# YTM32B1LE0 register map
Vendor: YTMicro; File version: 1.9
CPU: CM0PLUS r0p1, little endian, MPU, FPU, 2 interrupt priority bits
Registers are 32-bit, read-write, reset 0x0 unless marked. A register's access mark holds for its fields unless they carry their own. Offsets are from the block's base; [hi:lo] are bit positions; 'fields as' and 'values as' point back to an identical list.

## PCU — Power control unit
Base 0x4007D000; register names take the prefix PCU_
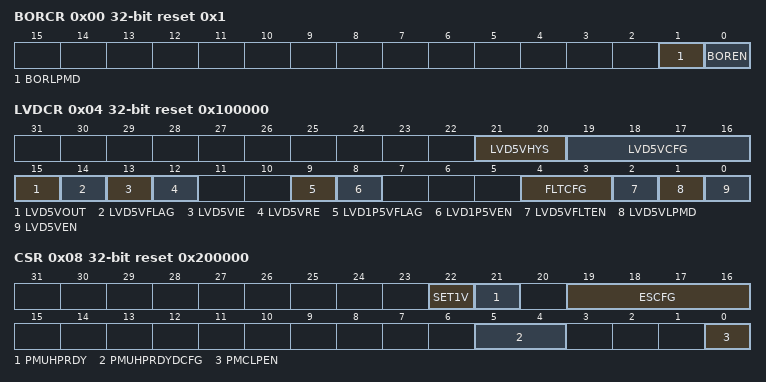
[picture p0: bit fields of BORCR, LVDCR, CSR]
0x00 BORCR reset 0x1
  [1] BORLPMD — BORLPMD Enable BOR Low Power Mode. That means BOR is enabled intermittently to saving power. The Power Saving efficiency is defined by ESCFG. BOREN must be set when BOR enters low power mode.
    0=BOR is not in Low Power Mode; 1=BOR is in Low Power Mode(Energy Saving Mode)
  [0] BOREN — BOREN Enable the BOR module. When BOR is enabled, a bor reset occurs when the chip power supply voltage falls below BOR threshold voltage(about 2.2V).
    0=BOR is disabled; 1=BOR is enabled
0x04 LVDCR reset 0x100000
  [21:20] LVD5VHYS — This field configure the LVD Hysteresis.
    0=0mV; 1=+­ 2.0%; 2=+­ 4.2%; 3=+­ 8.4%
  [19:16] LVD5VCFG — This field configures the LVD5V Threshold Voltage.
    0=1.860V; 1=2.120V; 2=2.370V; 3=2.630V; 4=2.870V; 5=3.120V; 6=3.390V; 7=3.650V; 8=3.910V; 9=4.160V; 10=4.360V; 11=4.530V; 12=4.720V; 13=4.910V
  [15] LVD5VOUT ro — This read only bit reflects the LVD5V detection result. If LVD5V glitch filter is enabled, this bit shows the filtered result.
    0=The supply voltage 5v is above LVD threshold; 1=The supply voltage 5v is below LVD threshold
  [14] LVD5VFLAG — Write 1 to clear this flag.
    values as LVD5VOUT
  [13] LVD5VIE — Enable/Disable LVD5V interrupt.
    0=Don't assert interrupt when LVD5VFLAG is set; 1=Assert a PCU interrupt when LVD5VFLAG is set
  [12] LVD5VRE — Enable/Disable LVD5V reset.
    0=Don't generate reset when the supply voltage 5v is below LVD threshold; 1=Generate reset when the supply voltage 5v is below LVD threshold
  [9] LVD1P5VFLAG — Write 1 to clear this flag.
    0=The supply voltage 1.5v is above LVD threshold; 1=The supply voltage 1.5v is below LVD threshold
  [8] LVD1P5VEN — LVD1P5VEN enable the low-voltage detect of VDD1p5v.
    0=LVD is disabled; 1=LVD is enabled
  [4:3] FLTCFG — There’s an optional digital glitch filter for LVD5VOUT. The Filter Clock is SIRC divided by 64 (31.25KHz) and the glitch filter width can be configured by FLTCFG. The glitches that width is shorter than (FLTCFG+1)*(the period of SIRC multiplied by 64) can be filtered.
  [2] LVD5VFLTEN — When this bit is set, LVD5V glitch filter is enabled. The filter is also enabled if LVD5VLPMD is set no matter LVD5VFLTEN is set or not.
    0=LVD5VOUT is not filtered by Glitch Filter if LVD5VLPMD is not set; 1=LVD5VOUT is filtered by Glitch Filter
  [1] LVD5VLPMD — When this bit is set, LVD5V is turned on intermittently for saving power. The Power Saving efficiency is defined by ESCFG. LVD5VEN must be set when LVD5V enters low power mode.
    0=LVD is not in Low Power Mode; 1=LVD is in Low Power Mode(Energy Saving Mode)
  [0] LVD5VEN — LVD5VEN enable the low-voltage detect of VDD5v. After enabling LVD function, need wait for more than 3us settling time until LVD circuit is stable.
    0=LVD is disabled; 1=LVD is enabled
0x08 CSR reset 0x200000
  [22] SET1V — When set, the core supply will change to 1v if PMU is in low power mode.
    0=Core supply is 1.5v; 1=Set core supply to 1v
  [21] PMUHPRDY ro — When set, it means PMU is in high power mode. FIRC must work in high power mode. So, please make sure this bit is 1 before enable FIRC or switch some clock to FIRC.
    0=PMU is in low power mode; 1=PMU high power mode is ready
  [19:16] ESCFG — This field configures the Energy Saving efficiency. All values except those in the range described below are reserved.
    0=0.10% of normal mode, Sampling period=512ms; 1=0.20% of normal mode, Sampling period=256ms; 2=0.40% of normal mode, Sampling period=128ms; 3=0.80% of normal mode, Sampling period=64ms; 4=1.56% of normal mode, Sampling period=32ms; 5=3.10% of normal mode, Sampling period=16ms; 6=6.25% of normal mode, Sampling period=8ms; 7=12.5% of normal mode, Sampling period=4ms; 8=25.0% of normal mode, Sampling period=2ms; 9=50.0% of normal mode, Sampling period=1ms
  [5:4] PMUHPRDYDCFG — When PMUHPRDY is in posedge state, it will delay for some time to be 1. The delay length is determined by the configured value.
    0=The delay length is 80us; 1=The delay length is 40us; 2=The delay length is 20us
  [0] PMCLPEN — This bit is to control PMC to enter low power or not when chip enters low power mode.
    0=PMC remains at full power mode when chip enters low power mode; 1=PMC will enter low power mode when chip enters low power mode
